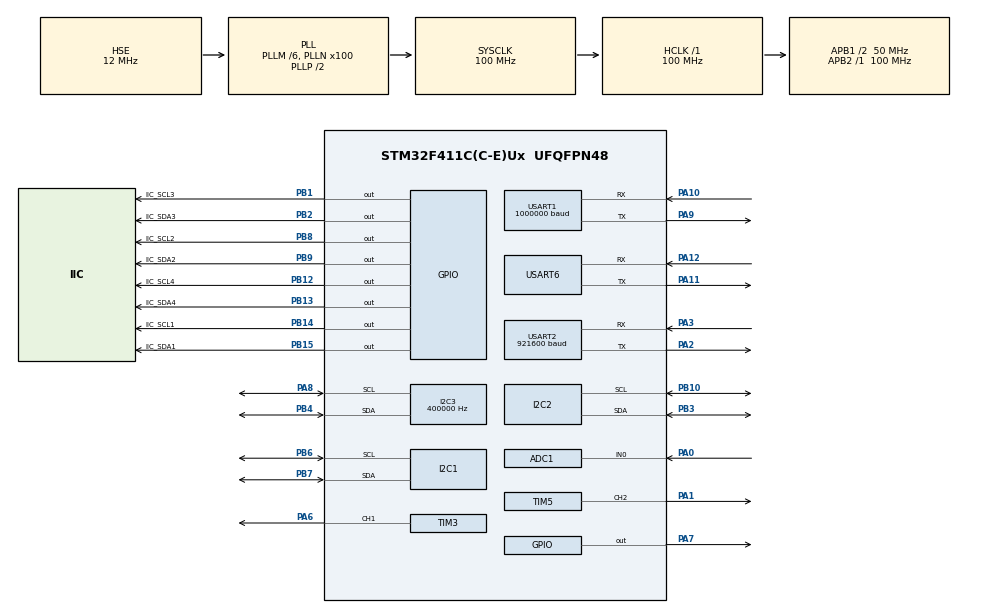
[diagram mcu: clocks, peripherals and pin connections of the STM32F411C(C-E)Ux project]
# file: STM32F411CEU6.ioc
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ADC1.Channel-0\#ChannelRegularConversion=ADC_CHANNEL_0
ADC1.DMAContinuousRequests=ENABLE
ADC1.NbrOfConversionFlag=1
ADC1.Rank-0\#ChannelRegularConversion=1
ADC1.SamplingTime-0\#ChannelRegularConversion=ADC_SAMPLETIME_3CYCLES
ADC1.master=1
Dma.ADC1.6.Direction=DMA_PERIPH_TO_MEMORY
Dma.ADC1.6.FIFOMode=DMA_FIFOMODE_DISABLE
Dma.ADC1.6.Instance=DMA2_Stream0
Dma.ADC1.6.MemDataAlignment=DMA_MDATAALIGN_HALFWORD
Dma.ADC1.6.MemInc=DMA_MINC_ENABLE
Dma.ADC1.6.Mode=DMA_CIRCULAR
Dma.ADC1.6.PeriphDataAlignment=DMA_PDATAALIGN_HALFWORD
Dma.ADC1.6.PeriphInc=DMA_PINC_DISABLE
Dma.ADC1.6.Priority=DMA_PRIORITY_LOW
Dma.Request0=USART6_TX
Dma.Request1=USART1_RX
Dma.Request2=USART1_TX
Dma.Request3=USART2_RX
Dma.Request4=USART2_TX
Dma.Request5=USART6_RX
Dma.Request6=ADC1
Dma.USART1_RX.1.Direction=DMA_PERIPH_TO_MEMORY
Dma.USART1_RX.1.FIFOMode=DMA_FIFOMODE_DISABLE
Dma.USART1_RX.1.Instance=DMA2_Stream2
Dma.USART1_RX.1.MemDataAlignment=DMA_MDATAALIGN_BYTE
Dma.USART1_RX.1.MemInc=DMA_MINC_ENABLE
Dma.USART1_RX.1.Mode=DMA_NORMAL
Dma.USART1_RX.1.PeriphDataAlignment=DMA_PDATAALIGN_BYTE
Dma.USART1_RX.1.PeriphInc=DMA_PINC_DISABLE
Dma.USART1_RX.1.Priority=DMA_PRIORITY_MEDIUM
Dma.USART1_TX.2.Direction=DMA_MEMORY_TO_PERIPH
Dma.USART1_TX.2.FIFOMode=DMA_FIFOMODE_DISABLE
Dma.USART1_TX.2.Instance=DMA2_Stream7
Dma.USART1_TX.2.MemDataAlignment=DMA_MDATAALIGN_BYTE
Dma.USART1_TX.2.MemInc=DMA_MINC_ENABLE
Dma.USART1_TX.2.Mode=DMA_NORMAL
Dma.USART1_TX.2.PeriphDataAlignment=DMA_PDATAALIGN_BYTE
Dma.USART1_TX.2.PeriphInc=DMA_PINC_DISABLE
Dma.USART1_TX.2.Priority=DMA_PRIORITY_MEDIUM
Dma.USART2_RX.3.Direction=DMA_PERIPH_TO_MEMORY
Dma.USART2_RX.3.FIFOMode=DMA_FIFOMODE_DISABLE
Dma.USART2_RX.3.Instance=DMA1_Stream5
Dma.USART2_RX.3.MemDataAlignment=DMA_MDATAALIGN_BYTE
Dma.USART2_RX.3.MemInc=DMA_MINC_ENABLE
Dma.USART2_RX.3.Mode=DMA_NORMAL
Dma.USART2_RX.3.PeriphDataAlignment=DMA_PDATAALIGN_BYTE
Dma.USART2_RX.3.PeriphInc=DMA_PINC_DISABLE
Dma.USART2_RX.3.Priority=DMA_PRIORITY_VERY_HIGH
Dma.USART2_TX.4.Direction=DMA_MEMORY_TO_PERIPH
Dma.USART2_TX.4.FIFOMode=DMA_FIFOMODE_DISABLE
Dma.USART2_TX.4.Instance=DMA1_Stream6
Dma.USART2_TX.4.MemDataAlignment=DMA_MDATAALIGN_BYTE
Dma.USART2_TX.4.MemInc=DMA_MINC_ENABLE
Dma.USART2_TX.4.Mode=DMA_NORMAL
Dma.USART2_TX.4.PeriphDataAlignment=DMA_PDATAALIGN_BYTE
Dma.USART2_TX.4.PeriphInc=DMA_PINC_DISABLE
Dma.USART2_TX.4.Priority=DMA_PRIORITY_VERY_HIGH
Dma.USART6_RX.5.Direction=DMA_PERIPH_TO_MEMORY
Dma.USART6_RX.5.FIFOMode=DMA_FIFOMODE_DISABLE
Dma.USART6_RX.5.Instance=DMA2_Stream1
Dma.USART6_RX.5.MemDataAlignment=DMA_MDATAALIGN_BYTE
Dma.USART6_RX.5.MemInc=DMA_MINC_ENABLE
Dma.USART6_RX.5.Mode=DMA_NORMAL
Dma.USART6_RX.5.PeriphDataAlignment=DMA_PDATAALIGN_BYTE
Dma.USART6_RX.5.PeriphInc=DMA_PINC_DISABLE
Dma.USART6_RX.5.Priority=DMA_PRIORITY_VERY_HIGH
Dma.USART6_TX.0.Direction=DMA_MEMORY_TO_PERIPH
Dma.USART6_TX.0.FIFOMode=DMA_FIFOMODE_DISABLE
Dma.USART6_TX.0.Instance=DMA2_Stream6
Dma.USART6_TX.0.MemDataAlignment=DMA_MDATAALIGN_BYTE
Dma.USART6_TX.0.MemInc=DMA_MINC_ENABLE
Dma.USART6_TX.0.Mode=DMA_NORMAL
Dma.USART6_TX.0.PeriphDataAlignment=DMA_PDATAALIGN_BYTE
Dma.USART6_TX.0.PeriphInc=DMA_PINC_DISABLE
Dma.USART6_TX.0.Priority=DMA_PRIORITY_VERY_HIGH
FREERTOS.Tasks01=UsartTask,2,2048,UsartTask_Entry,As weak,NULL,Dynamic,NULL,NULL;AlgorithmTask,2,2048,AlgorithmTask_Entry,As weak,NULL,Dynamic,NULL,NULL;SendTask,-3,2048,SendTask_Entry,As weak,NULL,Dynamic,NULL,NULL
FREERTOS.configENABLE_FPU=1
FREERTOS.configTOTAL_HEAP_SIZE=36000
FREERTOS.configUSE_NEWLIB_REENTRANT=0
I2C1.I2C_Mode=I2C_Fast
I2C2.I2C_Mode=I2C_Fast
I2C3.ClockSpeed=400000
I2C3.I2C_Mode=I2C_Fast
Mcu.Family=STM32F4
Mcu.Name=STM32F411C(C-E)Ux
Mcu.Package=UFQFPN48
NVIC.DMA1_Stream5_IRQn=true\:5\:0\:false\:false\:true\:true\:false\:true\:true
NVIC.DMA1_Stream6_IRQn=true\:5\:0\:false\:false\:true\:true\:false\:true\:true
NVIC.DMA2_Stream0_IRQn=true\:5\:0\:false\:false\:true\:true\:false\:true\:true
NVIC.DMA2_Stream1_IRQn=true\:5\:0\:false\:false\:true\:true\:false\:true\:true
NVIC.DMA2_Stream2_IRQn=true\:5\:0\:false\:false\:true\:true\:false\:true\:true
NVIC.DMA2_Stream6_IRQn=true\:5\:0\:false\:false\:true\:true\:false\:true\:true
NVIC.DMA2_Stream7_IRQn=true\:5\:0\:false\:false\:true\:true\:false\:true\:true
NVIC.PriorityGroup=NVIC_PRIORITYGROUP_4
NVIC.TIM1_UP_TIM10_IRQn=true\:5\:0\:false\:false\:true\:false\:false\:true\:true
NVIC.TimeBase=TIM1_UP_TIM10_IRQn
NVIC.TimeBaseIP=TIM10
NVIC.USART1_IRQn=true\:5\:0\:false\:false\:true\:true\:true\:true\:true
NVIC.USART2_IRQn=true\:5\:0\:false\:false\:true\:true\:true\:true\:true
NVIC.USART6_IRQn=true\:5\:0\:false\:false\:true\:true\:true\:true\:true
PA0-WKUP.Signal=ADCx_IN0
PA1.Signal=S_TIM5_CH2
PA10.Mode=Asynchronous
PA10.Signal=USART1_RX
PA11.Mode=Asynchronous
PA11.Signal=USART6_TX
PA12.Mode=Asynchronous
PA12.Signal=USART6_RX
PA13.Mode=Serial_Wire
PA13.Signal=SYS_JTMS-SWDIO
PA14.Mode=Serial_Wire
PA14.Signal=SYS_JTCK-SWCLK
PA2.Mode=Asynchronous
PA2.Signal=USART2_TX
PA3.Mode=Asynchronous
PA3.Signal=USART2_RX
PA6.Signal=S_TIM3_CH1
PA7.Signal=GPIO_Output
PA8.GPIO_Pu=GPIO_PULLUP
PA8.Mode=I2C
PA8.Signal=I2C3_SCL
PA9.Mode=Asynchronous
PA9.Signal=USART1_TX
PB1.GPIO_Label=IIC_SCL3
PB1.GPIO_PuPd=GPIO_PULLUP
PB1.GPIO_Speed=GPIO_SPEED_FREQ_VERY_HIGH
PB1.PinState=GPIO_PIN_SET
PB1.Signal=GPIO_Output
PB10.GPIO_Pu=GPIO_PULLUP
PB10.Mode=I2C
PB10.Signal=I2C2_SCL
PB12.GPIO_Label=IIC_SCL4
PB12.GPIO_PuPd=GPIO_PULLUP
PB12.GPIO_Speed=GPIO_SPEED_FREQ_VERY_HIGH
PB12.PinState=GPIO_PIN_SET
PB12.Signal=GPIO_Output
PB13.GPIO_Label=IIC_SDA4
PB13.GPIO_PuPd=GPIO_PULLUP
PB13.GPIO_Speed=GPIO_SPEED_FREQ_VERY_HIGH
PB13.PinState=GPIO_PIN_SET
PB13.Signal=GPIO_Output
PB14.GPIO_Label=IIC_SCL1
PB14.GPIO_PuPd=GPIO_PULLUP
PB14.GPIO_Speed=GPIO_SPEED_FREQ_VERY_HIGH
PB14.PinState=GPIO_PIN_SET
PB14.Signal=GPIO_Output
PB15.GPIO_Label=IIC_SDA1
PB15.GPIO_PuPd=GPIO_PULLUP
PB15.GPIO_Speed=GPIO_SPEED_FREQ_VERY_HIGH
PB15.PinState=GPIO_PIN_SET
PB15.Signal=GPIO_Output
PB2.GPIO_Label=IIC_SDA3
PB2.GPIO_PuPd=GPIO_PULLUP
PB2.GPIO_Speed=GPIO_SPEED_FREQ_VERY_HIGH
PB2.PinState=GPIO_PIN_SET
PB2.Signal=GPIO_Output
PB3.GPIO_Pu=GPIO_PULLUP
PB3.Mode=I2C
PB3.Signal=I2C2_SDA
PB4.GPIO_Pu=GPIO_PULLUP
PB4.Mode=I2C
PB4.Signal=I2C3_SDA
PB6.GPIO_Pu=GPIO_PULLUP
PB6.Mode=I2C
PB6.Signal=I2C1_SCL
PB7.GPIO_Pu=GPIO_PULLUP
PB7.Mode=I2C
PB7.Signal=I2C1_SDA
PB8.GPIO_Label=IIC_SCL2
PB8.GPIO_PuPd=GPIO_PULLUP
PB8.GPIO_Speed=GPIO_SPEED_FREQ_VERY_HIGH
PB8.PinState=GPIO_PIN_SET
PB8.Signal=GPIO_Output
PB9.GPIO_Label=IIC_SDA2
PB9.GPIO_PuPd=GPIO_PULLUP
PB9.GPIO_Speed=GPIO_SPEED_FREQ_VERY_HIGH
PB9.PinState=GPIO_PIN_SET
PB9.Signal=GPIO_Output
PH0\ -\ OSC_IN.Mode=HSE-External-Oscillator
PH0\ -\ OSC_IN.Signal=RCC_OSC_IN
PH1\ -\ OSC_OUT.Mode=HSE-External-Oscillator
PH1\ -\ OSC_OUT.Signal=RCC_OSC_OUT
ProjectManager.HeapSize=0x1000
ProjectManager.StackSize=0x1000
ProjectManager.TargetToolchain=STM32CubeIDE
RCC.48MHZClocksFreq_Value=50000000
RCC.AHBFreq_Value=100000000
RCC.APB1CLKDivider=RCC_HCLK_DIV2
RCC.APB1Freq_Value=50000000
RCC.APB1TimFreq_Value=100000000
RCC.APB2Freq_Value=100000000
RCC.APB2TimFreq_Value=100000000
RCC.CortexFreq_Value=100000000
RCC.HCLKFreq_Value=100000000
RCC.HSE_VALUE=12000000
RCC.HSI_VALUE=16000000
RCC.LSE_VALUE=32768
RCC.PLLM=6
RCC.PLLN=100
RCC.PLLSourceVirtual=RCC_PLLSOURCE_HSE
RCC.SYSCLKFreq_VALUE=100000000
RCC.SYSCLKSource=RCC_SYSCLKSOURCE_PLLCLK
RCC.VCOOutputFreq_Value=200000000
SH.ADCx_IN0.0=ADC1_IN0,IN0
SH.S_TIM3_CH1.0=TIM3_CH1,PWM Generation1 CH1
SH.S_TIM5_CH2.0=TIM5_CH2,PWM Generation2 CH2
STMicroelectronics.X-CUBE-ALGOBUILD.1.4.0.LibraryCcDSPOoLibraryJjDSPOoLibrary=true
TIM2.CounterMode=TIM_COUNTERMODE_UP
TIM2.Period=0xffffffff
TIM2.Prescaler=100-1
TIM3.Channel-PWM\ Generation1\ CH1=TIM_CHANNEL_1
TIM5.Channel-PWM\ Generation2\ CH2=TIM_CHANNEL_2
TIM5.Period=4294967295
USART1.BaudRate=1000000
USART1.VirtualMode=VM_ASYNC
USART2.BaudRate=921600
USART2.VirtualMode=VM_ASYNC
USART6.VirtualMode=VM_ASYNC
VP_FREERTOS_VS_CMSIS_V1.Mode=CMSIS_V1
VP_STMicroelectronics.X-CUBE-ALGOBUILD_VS_DSPOoLibraryJjLibrary_1.4.0_1.4.0.Mode=DSPOoLibraryJjLibrary
VP_SYS_VS_tim10.Mode=TIM10
VP_TIM2_VS_ClockSourceINT.Mode=Internal
board=custom

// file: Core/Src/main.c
/* USER CODE BEGIN Header */
/**
  ******************************************************************************
  * @file           : main.c
  * @brief          : Main program body
  ******************************************************************************
  * @attention
  *
  * Copyright (c) 2025 STMicroelectronics.
  * All rights reserved.
  *
  * This software is licensed under terms that can be found in the LICENSE file
  * in the root directory of this software component.
  * If no LICENSE file comes with this software, it is provided AS-IS.
  *
  ******************************************************************************
  */
/* USER CODE END Header */
#include "main.h"
#include "cmsis_os.h"
#include "adc.h"
#include "dma.h"
#include "i2c.h"
#include "tim.h"
#include "usart.h"
#include "gpio.h"

/* USER CODE BEGIN Includes */
#include "robot.h"

/* USER CODE END Includes */

void SystemClock_Config(void);
void MX_FREERTOS_Init(void);

int main(void)
{

  /* MCU Configuration--------------------------------------------------------*/

  /* Reset of all peripherals, Initializes the Flash interface and the Systick. */
  HAL_Init();

  /* Configure the system clock */
  SystemClock_Config();

  /* Initialize all configured peripherals */
  MX_GPIO_Init();
  MX_DMA_Init();
  MX_USART1_UART_Init();
  MX_I2C1_Init();
  MX_I2C2_Init();
  MX_I2C3_Init();
  MX_USART2_UART_Init();
  MX_USART6_UART_Init();
  MX_ADC1_Init();
  MX_TIM3_Init();
  MX_TIM5_Init();
  MX_TIM2_Init();
  /* USER CODE BEGIN 2 */
    HAL_GPIO_WritePin(GPIOA,GPIO_PIN_7,GPIO_PIN_SET);
    robot_init();

  /* USER CODE END 2 */

  /* Call init function for freertos objects (in cmsis_os2.c) */
  MX_FREERTOS_Init();

  /* Start scheduler */
  osKernelStart();

  /* We should never get here as control is now taken by the scheduler */

  /* Infinite loop */
  while (1)
  {

  }
}

void SystemClock_Config(void)
{
  RCC_OscInitTypeDef RCC_OscInitStruct = {0};
  RCC_ClkInitTypeDef RCC_ClkInitStruct = {0};

  /** Configure the main internal regulator output voltage
  */
  __HAL_RCC_PWR_CLK_ENABLE();
  __HAL_PWR_VOLTAGESCALING_CONFIG(PWR_REGULATOR_VOLTAGE_SCALE1);

  /** Initializes the RCC Oscillators according to the specified parameters
  * in the RCC_OscInitTypeDef structure.
  */
  RCC_OscInitStruct.OscillatorType = RCC_OSCILLATORTYPE_HSE;
  RCC_OscInitStruct.HSEState = RCC_HSE_ON;
  RCC_OscInitStruct.PLL.PLLState = RCC_PLL_ON;
  RCC_OscInitStruct.PLL.PLLSource = RCC_PLLSOURCE_HSE;
  RCC_OscInitStruct.PLL.PLLM = 6;
  RCC_OscInitStruct.PLL.PLLN = 100;
  RCC_OscInitStruct.PLL.PLLP = RCC_PLLP_DIV2;
  RCC_OscInitStruct.PLL.PLLQ = 4;
  if (HAL_RCC_OscConfig(&RCC_OscInitStruct) != HAL_OK)
  {
    Error_Handler();
  }

  /** Initializes the CPU, AHB and APB buses clocks
  */
  RCC_ClkInitStruct.ClockType = RCC_CLOCKTYPE_HCLK|RCC_CLOCKTYPE_SYSCLK
                              |RCC_CLOCKTYPE_PCLK1|RCC_CLOCKTYPE_PCLK2;
  RCC_ClkInitStruct.SYSCLKSource = RCC_SYSCLKSOURCE_PLLCLK;
  RCC_ClkInitStruct.AHBCLKDivider = RCC_SYSCLK_DIV1;
  RCC_ClkInitStruct.APB1CLKDivider = RCC_HCLK_DIV2;
  RCC_ClkInitStruct.APB2CLKDivider = RCC_HCLK_DIV1;

  if (HAL_RCC_ClockConfig(&RCC_ClkInitStruct, FLASH_LATENCY_3) != HAL_OK)
  {
    Error_Handler();
  }
}

void HAL_TIM_PeriodElapsedCallback(TIM_HandleTypeDef *htim)
{
  if (htim->Instance == TIM10)
  {
    HAL_IncTick();
  }
}

void Error_Handler(void)
{
  __disable_irq();
  while (1)
  {
  }
}
